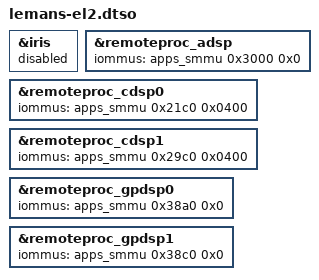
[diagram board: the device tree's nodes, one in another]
// SPDX-License-Identifier: BSD-3-Clause
/*
 * Copyright (c) Qualcomm Technologies, Inc. and/or its subsidiaries.
 */

/*
 * Lemans specific modifications required to boot in EL2.
 */

/dts-v1/;
/plugin/;

&iris {
	/* More driver work is needed */
	status = "disabled";
};

/*
 * When running under Gunyah, remote processor firmware IOMMU streams is
 * controlled by the Gunyah however when we take ownership of it in EL2,
 * we need to configure it properly to use remote processor.
 */
&remoteproc_adsp {
	iommus = <&apps_smmu 0x3000 0x0>;
};

&remoteproc_cdsp0 {
	iommus = <&apps_smmu 0x21c0 0x0400>;
};

&remoteproc_cdsp1 {
	iommus = <&apps_smmu 0x29c0 0x0400>;
};

&remoteproc_gpdsp0 {
       iommus = <&apps_smmu 0x38a0 0x0>;
};

&remoteproc_gpdsp1 {
       iommus = <&apps_smmu 0x38c0 0x0>;
};
